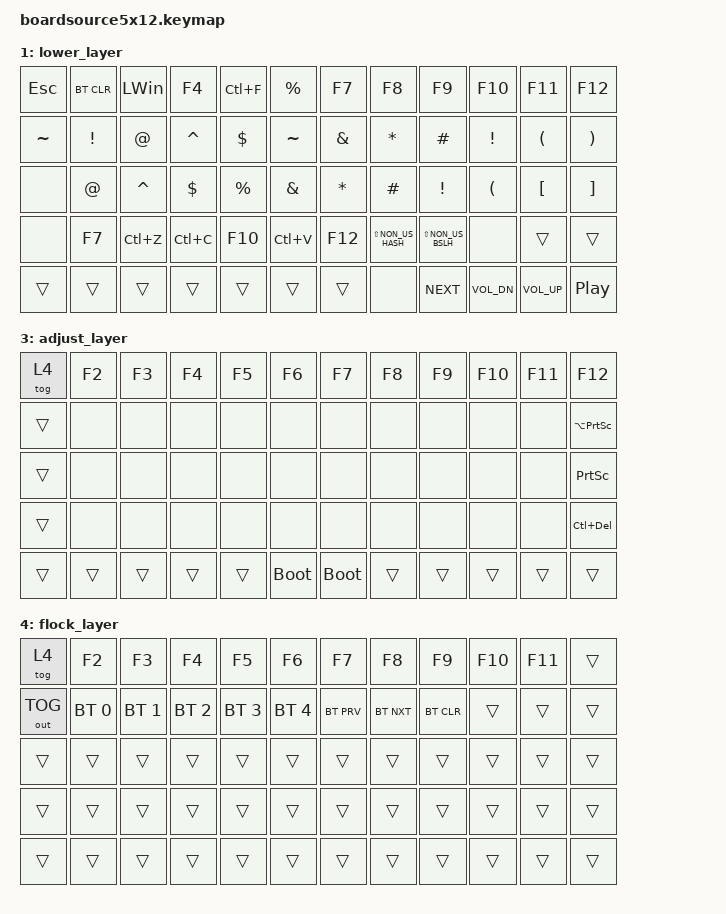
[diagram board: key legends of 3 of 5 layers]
/*
 * Copyright (c) 2021 The ZMK Contributors
 *
 * SPDX-License-Identifier: MIT
 */
 
#include <behaviors.dtsi>
#include <dt-bindings/zmk/keys.h>
#include <dt-bindings/zmk/bt.h>
#include <dt-bindings/zmk/outputs.h>



#define DEFAULT 0
#define LOWER   1
#define RAISE   2
#define ADJUST  3

&mt {
    tapping-term-ms = <150>;
};  

/ {
    combos {
        compatible = "zmk,combos";
        combo_esc {
            timeout-ms = <150>;
            key-positions = <0 1>;
            bindings = <&kp ESC>;
        };
    };
};


/ {
    keymap {
        compatible = "zmk,keymap";

        default_layer {
            // ------------------------------------------------------------------------------------------
            // |  ESC  |  1   |  2   |  3   |  4   |  5   |   6   |  7    |  8   |  9   |   0   | BSPC  |
            // |  TAB  |  Q   |  W   |  E   |  R   |  T   |   Y   |  U    |  I   |  E   |   I   |  O    |
            // | SHIFT |  A   |  S   |  D   |  F   |  G   |   H   |  J    |  K   |  L   |   ;   |  '    |
            // | CTRL  |  Z   |  X   |  C   |  V   |  B   |   N   |  M    |  ,   |  .   |   /   | ENTER |
            // |ADJUST | LCTL | LALT | LGUI | LOWR | SPACE| SPACE |  RAIS | LARW | DARW | UARW  | RARW  |


            bindings = <
               &kp DELETE       &kp ESC    &kp Q       &kp W    &kp F      &kp P       &kp B              &kp J                  &kp L       &kp U         &kp Y        &kp APOS
               &kp LC(X)    &kp LC(A)              &kp A       &kp R    &kp S      &kp T       &kp G              &kp M                 &kp N       &kp E         &kp I        &kp O
               &kp LC(C)  &kp LC(Z)           &kp Z       &kp X      &kp C      &kp D       &kp V              &kp K                 &kp H       &kp COMMA       &kp DOT    &kp FSLH
               &kp LC(V)  &kp LCTL        &kp LC(S)       &kp LALT   &mo LOWER   &mt LC(BSPC) BSPC    &kp LSHFT  &lt RAISE SPACE        &kp ENTER      &kp TAB      &kp MINUS    &kp SEMI
          
            >;
        };

        lower_layer {
            // -------------------------------------------------------------------------------------------
            // |  ESC  |  F2  |  F3  |  F4  |  F5  |  F6  |   F7  |  F8   |  F9  | F10  |  F11  |  F12  |
            // |   ~   |  !   |  @   |  #   |  $   |  %   |   ^   |   &   |  *   |  (   |   )   |  DEL  |
            // |       |  F1  |  F2  |  F3  |  F4  |  F5  |   F6  |   _   |  +   |  {   |   }   |   |   |
            // |       |  F7  |  F8  |  F9  |  F10 |  F11 |   F12 | LS(#) |LS(|) |      |       |       |
            // |       |      |      |      |      |      |       |       | NEXT | Vol- | Vol+ | PLAY   |
            bindings = <
                &kp ESC   &bt BT_CLR   &kp LWIN   &kp F4   &kp LC(F)    &kp PRCNT       &kp F7          &kp F8              &kp F9              &kp F10      &kp F11          &kp F12
                &kp TILDE &kp EXCL &kp AT   &kp CARET    &kp DLLR  &kp TILDE    &kp AMPS       &kp ASTRK            &kp HASH           &kp EXCL     &kp LPAR         &kp RPAR
               &none    &kp AT   &kp CARET   &kp DLLR   &kp PRCNT    &kp AMPS       &kp ASTRK          &kp HASH           &kp EXCL            &kp LPAR     &kp LBKT         &kp RBKT
                &none    &kp F7   &kp LC(Z)   &kp LC(C)   &kp F10   &kp LC(V)      &kp F12         &kp LS(NON_US_HASH) &kp LS(NON_US_BSLH) &none       &trans           &trans
                &trans   &trans   &trans   &trans    &trans    &trans       &trans          &none               &kp C_NEXT          &kp C_VOL_DN &kp C_VOL_UP     &kp C_PLAY_PAUSE 
            >;
        };

        raise_layer {
            // ------------------------------------------------------------------------------------------
            // |  ESC  |  F2  |  F3  |  F4  |  F5  |  F6  |  F7   |  F8   |  F9  | F10  |  F11  |  F12  |
            // |   ~   |  1   |  2   |  3   |  4   |  5   |  6    |   7   |  8   |  9   |   0   |  DEL  |
            // |  DEL  |  F1  |  F2  |  F3  |  F4  |  F5  |  F6   |   -   |  =   |  [   |   ]   |   \   |
            // |       |  F7  |  F8  |  F9  |  F10 |  F11 |  F12  |   #   |  |   |      |       |       |
            // |       |      |      |      |      |      |       |       |       |      |      |       |
            bindings = <
                &kp ESC   &none   &kp HOME   &kp HOME   &kp UP    &kp END  &kp C_VOLUME_UP    &kp C_NEXT          &kp N7          &kp N8      &kp N9          &kp ASTERISK
                &kp TILDE &kp N1   &trans   &kp LEFT   &kp DOWN    &kp RIGHT  &kp C_VOLUME_DOWN    &kp C_PREVIOUS          &kp N4          &kp N5       &kp N6           &kp FSLH
                &kp DEL   &kp F1   &kp LC(Z)   &kp LC(LEFT)   &kp F4    &kp   LC(RIGHT)        &kp C_MUTE    &kp C_PLAY_PAUSE  &kp N1       &kp N2     &kp N3         &kp PLUS
                &trans    &kp F7   &kp F8   &kp F9   &kp F10   &kp BSPC         &kp F12   &kp NON_US_HASH &kp EQUAL &kp N0       &kp N0           &kp MINUS
                
            >;
        };

        adjust_layer {
            // ------------------------------------------------------------------------------------------
            // |tog(4)|  F2  |  F3  |  F4  |  F5  |  F6  |  F7  |  F8  |  F9  |  F10 |  F11 |    F12    |
            // |      |  NA  |  NA  |  NA  |  NA  |  NA  |  NA  |  NA  |  NA  |  NA  |  NA  |LALT(PRTSN)|
            // |      |  NA  |  NA  |  NA  |  NA  |  NA  |  NA  |  NA  |  NA  |  NA  |  NA  |   PRTSN   |
            // |      |  NA  |  NA  |  NA  |  NA  |  NA  |  NA  |  NA  |  NA  |  NA  |  NA  |LCTRL(DEL) |
            // |      |      |      |      |      |BOOTLD|BOOTLD|      |      |      |      |           |
            bindings = <
                &tog 4 &kp F2 &kp F3 &kp F4 &kp F5 &kp F6 &kp F7 &kp F8 &kp F9 &kp F10 &kp F11 &kp F12
                &trans &none  &none  &none  &none  &none  &none  &none  &none  &none   &none   &kp LA(PSCRN)
                &trans &none  &none  &none  &none  &none  &none  &none  &none  &none   &none   &kp PSCRN
                &trans &none  &none  &none  &none  &none  &none  &none  &none  &none   &none   &kp LC(DEL)
                &trans &trans &trans &trans &trans &bootloader   &bootloader &trans &trans &trans &trans  &trans
            >;
        };

        flock_layer {
            // ----------------------------------------------------------------------------------------------
            // |tog(4) |  F2    |   F3   |   F4   |   F5   |   F6   |  F7  |  F8  |  F9  | F10 | F11 |      |
            // |out tog|BT_SEL 0|BT_SEL 1|BT_SEL 2|BT_SEL 3|BT_SEL 4|BT_PRV|BT_NXT|BT_CLR|     |     |      |
            // |       |        |        |        |        |        |      |      |      |     |     |      |
            // |       |        |        |        |        |        |      |      |      |     |     |      |
            // |       |        |        |        |        |        |      |      |      |     |     |      |
            bindings = <
                &tog 4       &kp F2       &kp F3       &kp F4       &kp F5       &kp F6       &kp F7     &kp F8     &kp F9     &kp F10 &kp F11 &trans
                &out OUT_TOG &bt BT_SEL 0 &bt BT_SEL 1 &bt BT_SEL 2 &bt BT_SEL 3 &bt BT_SEL 4 &bt BT_PRV &bt BT_NXT &bt BT_CLR &trans  &trans  &trans
                &trans       &trans       &trans       &trans       &trans       &trans       &trans     &trans     &trans     &trans  &trans  &trans
                &trans       &trans       &trans       &trans       &trans       &trans       &trans     &trans     &trans     &trans  &trans  &trans
                &trans       &trans       &trans       &trans       &trans       &trans       &trans     &trans     &trans     &trans  &trans  &trans
            >;
        };
    };
};
